# K1921VK028 register map
Vendor: NIIET; Series: K1921VKx; File version: 2.17
CPU: CM4 r0p1, little endian, MPU, FPU, 4 interrupt priority bits
Registers are 32-bit, read-write, reset 0x0 unless marked. A register's access mark holds for its fields unless they carry their own. Offsets are from the block's base; [hi:lo] are bit positions.

## QEP0 — QEP controller registers
Base 0x400AA000
Same registers: QEP1 0x400AB000, QEP2 0x400AC000, QEP3 0x400AD000
0x00 QPOSCNT — Position Counter register
  [31:0] VAL
0x04 QPOSINIT — Position Counter Initialization register
  [31:0] VAL
0x08 QPOSMAX — Maximum Position Count register
  [31:0] VAL
0x0C QPOSCMP — Position-compare register
  [31:0] VAL
0x10 QPOSILAT ro — Index Position Latch register
  [31:0] VAL
0x14 QPOSSLAT ro — Strobe Position Latch register
  [31:0] VAL
0x18 QPOSLAT ro — Position Counter Latch register
  [31:0] VAL
0x1C QUTMR — Unit Timer register
  [31:0] VAL
0x20 QUPRD — Unit Period register
  [31:0] VAL
0x24 QWDTMR — Watchdog Timer register
  [31:0] VAL
0x28 QWDPRD — Watchdog Period register
  [31:0] VAL
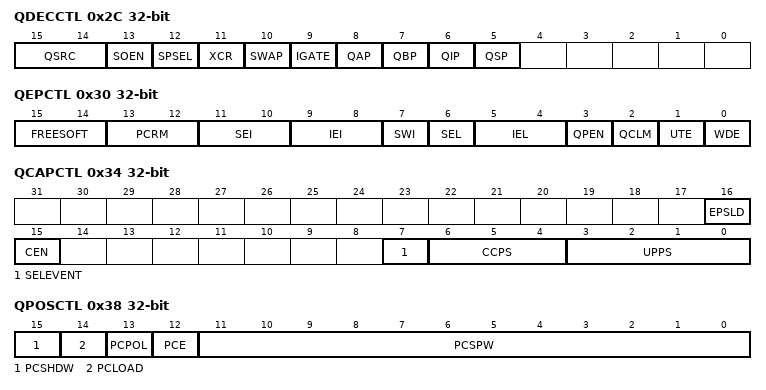
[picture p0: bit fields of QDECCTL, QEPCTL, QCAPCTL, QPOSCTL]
0x2C QDECCTL — Decoder Control register
  [15:14] QSRC
    0=quadrature mode; 1=count/direction mode; 2=Up (count up); 3=Down (count down)
  [13] SOEN — Sync output-enable
  [12] SPSEL — Sync output pin selection
  [11] XCR — External clock rate
  [10] SWAP — Swap quadrature clock inputs
  [9] IGATE — Index pulse gating option
  [8] QAP — QEPA input polarity
  [7] QBP — QEPB input polarity
  [6] QIP — QEPI input polarity
  [5] QSP — QEPS input polarity
0x30 QEPCTL — Control register
  [15:14] FREESOFT
    0=Stop (counters are blocked); 1=StopAtOvf (stop after overflow); 2=Free (no count stop in debug mode)
  [13:12] PCRM
    0=Ind (reset on index); 1=PosMax (reset on max position count); 2=FirstInd (reset on the first index); 3=Time (reset on time counter)
  [11:10] SEI
    0=no initialization; 2=QEPSPos (init on posedge QEPI); 3=QEPSDir (init depends on direction - on posedge if direction is up, on negedge if direction is down)
  [9:8] IEI
    0=no initialization; 2=QEPIPos (init on posedge QEPI); 3=QEPINeg (init on negedge QEPI)
  [7] SWI — Software initialization of position counter
  [6] SEL — Strobe event latch of position counter
  [5:4] IEL
    0=NoLatch (no position counter latch); 1=IndPos (latch on index signal posedge); 2=IndNeg (latch on index signal negedge); 3=IndMark (latch on index marker)
  [3] QPEN — Quadrature position counter enable/software reset
  [2] QCLM — QEP capture latch mode
  [1] UTE — QEP unit timer enable
  [0] WDE — QEP watchdog enable
0x34 QCAPCTL — Capture Control register
  [16] EPSLD — Enhanced prescalers load
  [15] CEN — Enable eQEP capture
  [7] SELEVENT — Reset timer control
  [6:4] CCPS
    0=Disable (no divider); 1=Div2 (sysclk divided by 2); 2=Div4 (sysclk divided by 4); 3=Div8 (sysclk divided by 8); 4=Div16 (sysclk divided by 16); 5=Div32 (sysclk divided by 32); 6=Div64 (sysclk divided by 64); 7=Div128 (sysclk divided by 128)
  [3:0] UPPS
    0=Disable (quad signal not divided); 1=Div2 (quad signal divided by 2); 2=Div4 (quad signal divided by 4); 3=Div8 (quad signal divided by 8); 4=Div16 (quad signal divided by 16); 5=Div32 (quad signal divided by 32); 6=Div64 (quad signal divided by 64); 7=Div128 (quad signal divided by 128); 8=Div256 (quad signal divided by 256); 9=Div512 (quad signal divided by 512); 10=Div1024 (quad signal divided by 1024); 11=Div2048 (quad signal divided by 2048)
0x38 QPOSCTL — Position-compare Control register
  [15] PCSHDW — Position-compare shadow enable
  [14] PCLOAD — Position-compare shadow load mode
  [13] PCPOL — Polarity of sync output
  [12] PCE — Position-compare enable/disable
  [11:0] PCSPW
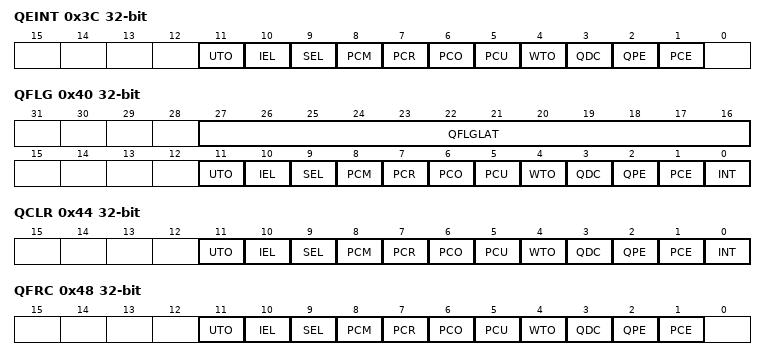
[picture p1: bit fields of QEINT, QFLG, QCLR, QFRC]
0x3C QEINT — Interrupt Enable register
  [11] UTO — Unit time out interrupt enable
  [10] IEL — Index event latch interrupt enable
  [9] SEL — Strobe event latch interrupt enable
  [8] PCM — Position-compare match interrupt enable
  [7] PCR — Position-compare ready interrupt enable
  [6] PCO — Position counter overflow interrupt enable
  [5] PCU — Position counter underflow interrupt enable
  [4] WTO — Watchdog time out interrupt enable
  [3] QDC — Quadrature direction change interrupt enable
  [2] QPE — Quadrature phase error interrupt enable
  [1] PCE — Position counter error interrupt enable
0x40 QFLG ro — Interrupt Flag register
  [27:16] QFLGLAT — Latches QFLG[11:0] on every QPOSCNT read
  [11] UTO — Unit time out interrupt flag
  [10] IEL — Index event latch interrupt flag
  [9] SEL — Strobe event latch interrupt flag
  [8] PCM — QEP compare match event interrupt flag
  [7] PCR — Position-compare ready interrupt flag
  [6] PCO — Position counter overflow interrupt flag
  [5] PCU — Position counter underflow interrupt flag
  [4] WTO — Watchdog timeout interrupt flag
  [3] QDC — Quadrature direction change interrupt flag
  [2] QPE — Quadrature phase error interrupt flag
  [1] PCE — Position counter error interrupt flag
  [0] INT — Global interrupt status flag
0x44 QCLR wo — Interrupt Clear register
  [11] UTO — Clear unit time out interrupt flag
  [10] IEL — Clear index event latch interrupt flag
  [9] SEL — Clear strobe event latch interrupt flag
  [8] PCM — Clear eQEP compare match event interrupt flag
  [7] PCR — Clear position-compare ready interrupt flag
  [6] PCO — Clear position counter overflow interrupt flag
  [5] PCU — Clear position counter underflow interrupt flag
  [4] WTO — Clear watchdog timeout interrupt flag
  [3] QDC — Clear quadrature direction change interrupt flag
  [2] QPE — Clear quadrature phase error interrupt flag
  [1] PCE — Clear position counter error interrupt flag
  [0] INT — Global interrupt clear flag
0x48 QFRC wo — Interrupt Force register
  [11] UTO — Force unit time out interrupt
  [10] IEL — Force index event latch interrupt
  [9] SEL — Force strobe event latch interrupt
  [8] PCM — Force position-compare match interrupt
  [7] PCR — Force position-compare ready interrupt
  [6] PCO — Force position counter overflow interrupt
  [5] PCU — Force position counter underflow interrupt
  [4] WTO — Force watchdog time out interrupt
  [3] QDC — Force quadrature direction change interrupt
  [2] QPE — Force quadrature phase error interrupt
  [1] PCE — Force position counter error interrupt
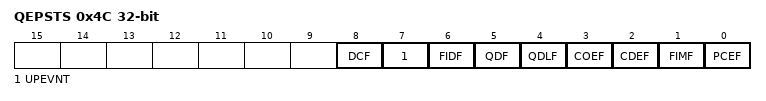
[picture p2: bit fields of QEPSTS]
0x4C QEPSTS — Status register
  [8] DCF — Direction change flag
  [7] UPEVNT — Unit position event flag
  [6] FIDF ro — Direction on the first index marker
  [5] QDF ro — Quadrature direction flag
  [4] QDLF — QEP direction latch flag
  [3] COEF — Capture overflow error flag
  [2] CDEF — Capture direction error flag
  [1] FIMF — First index marker flag
  [0] PCEF ro — Position counter error flag
0x50 QCTMR — Capture Timer register
  [31:0] VAL
0x54 QCPRD — Capture Period register
  [31:0] VAL
0x58 QCTMRLAT ro — Capture Timer Latch register
  [31:0] VAL
0x5C QCPRDLAT ro — Capture Period Latch register
  [31:0] VAL
0x60 DMAREQ — DMA request register
  [0] DMAEN — DMA request enable
0x70 INTCLR — Clear active interrupt register
  [0] INT — Active interrupt by read, write 1 to clear interrupt
